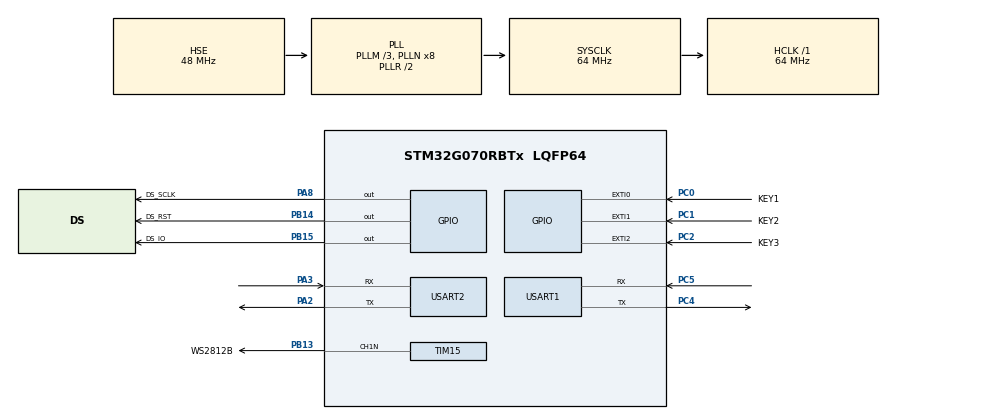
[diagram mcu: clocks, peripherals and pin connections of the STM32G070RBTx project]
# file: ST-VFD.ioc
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Dma.Request0=USART2_TX
Dma.Request1=USART2_RX
Dma.Request2=TIM15_CH1
Dma.TIM15_CH1.2.Direction=DMA_MEMORY_TO_PERIPH
Dma.TIM15_CH1.2.EventEnable=DISABLE
Dma.TIM15_CH1.2.Instance=DMA1_Channel3
Dma.TIM15_CH1.2.MemDataAlignment=DMA_MDATAALIGN_WORD
Dma.TIM15_CH1.2.MemInc=DMA_MINC_ENABLE
Dma.TIM15_CH1.2.Mode=DMA_NORMAL
Dma.TIM15_CH1.2.PeriphDataAlignment=DMA_PDATAALIGN_WORD
Dma.TIM15_CH1.2.PeriphInc=DMA_PINC_DISABLE
Dma.TIM15_CH1.2.Polarity=HAL_DMAMUX_REQ_GEN_RISING
Dma.TIM15_CH1.2.Priority=DMA_PRIORITY_LOW
Dma.TIM15_CH1.2.RequestNumber=1
Dma.TIM15_CH1.2.SignalID=NONE
Dma.TIM15_CH1.2.SyncEnable=DISABLE
Dma.TIM15_CH1.2.SyncPolarity=HAL_DMAMUX_SYNC_NO_EVENT
Dma.TIM15_CH1.2.SyncRequestNumber=1
Dma.TIM15_CH1.2.SyncSignalID=NONE
Dma.USART2_RX.1.Direction=DMA_PERIPH_TO_MEMORY
Dma.USART2_RX.1.EventEnable=DISABLE
Dma.USART2_RX.1.Instance=DMA1_Channel2
Dma.USART2_RX.1.MemDataAlignment=DMA_MDATAALIGN_BYTE
Dma.USART2_RX.1.MemInc=DMA_MINC_ENABLE
Dma.USART2_RX.1.Mode=DMA_NORMAL
Dma.USART2_RX.1.PeriphDataAlignment=DMA_PDATAALIGN_BYTE
Dma.USART2_RX.1.PeriphInc=DMA_PINC_DISABLE
Dma.USART2_RX.1.Polarity=HAL_DMAMUX_REQ_GEN_RISING
Dma.USART2_RX.1.Priority=DMA_PRIORITY_MEDIUM
Dma.USART2_RX.1.RequestNumber=1
Dma.USART2_RX.1.SignalID=NONE
Dma.USART2_RX.1.SyncEnable=DISABLE
Dma.USART2_RX.1.SyncPolarity=HAL_DMAMUX_SYNC_NO_EVENT
Dma.USART2_RX.1.SyncRequestNumber=1
Dma.USART2_RX.1.SyncSignalID=NONE
Dma.USART2_TX.0.Direction=DMA_MEMORY_TO_PERIPH
Dma.USART2_TX.0.EventEnable=DISABLE
Dma.USART2_TX.0.Instance=DMA1_Channel1
Dma.USART2_TX.0.MemDataAlignment=DMA_MDATAALIGN_BYTE
Dma.USART2_TX.0.MemInc=DMA_MINC_ENABLE
Dma.USART2_TX.0.Mode=DMA_NORMAL
Dma.USART2_TX.0.PeriphDataAlignment=DMA_PDATAALIGN_BYTE
Dma.USART2_TX.0.PeriphInc=DMA_PINC_DISABLE
Dma.USART2_TX.0.Polarity=HAL_DMAMUX_REQ_GEN_RISING
Dma.USART2_TX.0.Priority=DMA_PRIORITY_MEDIUM
Dma.USART2_TX.0.RequestNumber=1
Dma.USART2_TX.0.SignalID=NONE
Dma.USART2_TX.0.SyncEnable=DISABLE
Dma.USART2_TX.0.SyncPolarity=HAL_DMAMUX_SYNC_NO_EVENT
Dma.USART2_TX.0.SyncRequestNumber=1
Dma.USART2_TX.0.SyncSignalID=NONE
Mcu.Family=STM32G0
Mcu.Name=STM32G070RBTx
Mcu.Package=LQFP64
NVIC.DMA1_Channel1_IRQn=true\:0\:0\:false\:false\:true\:false\:true\:true
NVIC.DMA1_Channel2_3_IRQn=true\:0\:0\:false\:false\:true\:false\:true\:true
PA13.Mode=Serial_Wire
PA13.Signal=SYS_SWDIO
PA14-BOOT0.Mode=Serial_Wire
PA14-BOOT0.Signal=SYS_SWCLK
PA2.Mode=Asynchronous
PA2.Signal=USART2_TX
PA3.Mode=Asynchronous
PA3.Signal=USART2_RX
PA8.GPIO_Label=DS_SCLK
PA8.Signal=GPIO_Output
PB13.GPIO_Label=WS2812B
PB13.GPIO_Speed=GPIO_SPEED_FREQ_VERY_HIGH
PB13.Mode=PWM Generation1 CH1N
PB13.PinState=GPIO_PIN_RESET
PB13.Signal=TIM15_CH1N
PB14.GPIO_Label=DS_RST
PB14.Signal=GPIO_Output
PB15.GPIO_Label=DS_IO
PB15.Signal=GPIO_Output
PC0.GPIO_Label=KEY1
PC0.GPIO_ModeDefaultEXTI=GPIO_MODE_IT_FALLING
PC0.Signal=GPXTI0
PC1.GPIO_Label=KEY2
PC1.GPIO_ModeDefaultEXTI=GPIO_MODE_IT_FALLING
PC1.Signal=GPXTI1
PC2.GPIO_Label=KEY3
PC2.GPIO_ModeDefaultEXTI=GPIO_MODE_IT_FALLING
PC2.Signal=GPXTI2
PC4.Mode=Asynchronous
PC4.Signal=USART1_TX
PC5.Mode=Asynchronous
PC5.Signal=USART1_RX
PF0-OSC_IN\ (PF0).Mode=HSE-External-Oscillator
PF0-OSC_IN\ (PF0).Signal=RCC_OSC_IN
PF1-OSC_OUT\ (PF1).Mode=HSE-External-Oscillator
PF1-OSC_OUT\ (PF1).Signal=RCC_OSC_OUT
ProjectManager.HeapSize=0x200
ProjectManager.StackSize=0x400
ProjectManager.TargetToolchain=STM32CubeIDE
RCC.ADCFreq_Value=64000000
RCC.AHBFreq_Value=64000000
RCC.CortexFreq_Value=64000000
RCC.EXTERNAL_CLOCK_VALUE=48000
RCC.HCLKFreq_Value=64000000
RCC.HSE_VALUE=48000000
RCC.HSI_VALUE=16000000
RCC.LSE_VALUE=32768
RCC.PLLM=RCC_PLLM_DIV3
RCC.PLLSourceVirtual=RCC_PLLSOURCE_HSE
RCC.SYSCLKFreq_VALUE=64000000
RCC.SYSCLKSource=RCC_SYSCLKSOURCE_PLLCLK
RCC.VCOOutputFreq_Value=128000000
TIM15.Channel-PWM\ Generation1\ CH1N=TIM_CHANNEL_1
TIM15.Period=79
TIM6.Prescaler=63
USART1.VirtualMode-Asynchronous=VM_ASYNC
USART2.VirtualMode-Asynchronous=VM_ASYNC
VP_SYS_VS_DBSignals.Mode=DisableDeadBatterySignals
VP_TIM15_VS_ClockSourceINT.Mode=Internal
VP_TIM6_VS_ClockSourceINT.Mode=Enable_Timer
board=custom

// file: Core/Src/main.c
/* USER CODE BEGIN Header */
/**
  ******************************************************************************
  * @file           : main.c
  * @brief          : Main program body
  ******************************************************************************
  * @attention
  *
  * Copyright (c) 2023 STMicroelectronics.
  * All rights reserved.
  *
  * This software is licensed under terms that can be found in the LICENSE file
  * in the root directory of this software component.
  * If no LICENSE file comes with this software, it is provided AS-IS.
  *
  ******************************************************************************
  */
/* USER CODE END Header */
#include "main.h"
#include "dma.h"
#include "tim.h"
#include "usart.h"
#include "gpio.h"

/* USER CODE BEGIN Includes */
#include "index.h"
/* USER CODE END Includes */

void SystemClock_Config(void);

int main(void)
{

  /* MCU Configuration--------------------------------------------------------*/

  /* Reset of all peripherals, Initializes the Flash interface and the Systick. */
  HAL_Init();

  /* Configure the system clock */
  SystemClock_Config();

  /* Initialize all configured peripherals */
  MX_GPIO_Init();
  MX_DMA_Init();
  MX_USART1_UART_Init();
  MX_USART2_UART_Init();
  MX_TIM6_Init();
  MX_TIM15_Init();

  /* Infinite loop */
  /* USER CODE BEGIN WHILE */
  while (1)
  {
      Run_Service();
    /* USER CODE END WHILE */

  }
}

void SystemClock_Config(void)
{
  RCC_OscInitTypeDef RCC_OscInitStruct = {0};
  RCC_ClkInitTypeDef RCC_ClkInitStruct = {0};

  /** Configure the main internal regulator output voltage
  */
  HAL_PWREx_ControlVoltageScaling(PWR_REGULATOR_VOLTAGE_SCALE1);

  /** Initializes the RCC Oscillators according to the specified parameters
  * in the RCC_OscInitTypeDef structure.
  */
  RCC_OscInitStruct.OscillatorType = RCC_OSCILLATORTYPE_HSE;
  RCC_OscInitStruct.HSEState = RCC_HSE_ON;
  RCC_OscInitStruct.PLL.PLLState = RCC_PLL_ON;
  RCC_OscInitStruct.PLL.PLLSource = RCC_PLLSOURCE_HSE;
  RCC_OscInitStruct.PLL.PLLM = RCC_PLLM_DIV3;
  RCC_OscInitStruct.PLL.PLLN = 8;
  RCC_OscInitStruct.PLL.PLLP = RCC_PLLP_DIV2;
  RCC_OscInitStruct.PLL.PLLR = RCC_PLLR_DIV2;
  if (HAL_RCC_OscConfig(&RCC_OscInitStruct) != HAL_OK)
  {
    Error_Handler();
  }

  /** Initializes the CPU, AHB and APB buses clocks
  */
  RCC_ClkInitStruct.ClockType = RCC_CLOCKTYPE_HCLK|RCC_CLOCKTYPE_SYSCLK
                              |RCC_CLOCKTYPE_PCLK1;
  RCC_ClkInitStruct.SYSCLKSource = RCC_SYSCLKSOURCE_PLLCLK;
  RCC_ClkInitStruct.AHBCLKDivider = RCC_SYSCLK_DIV1;
  RCC_ClkInitStruct.APB1CLKDivider = RCC_HCLK_DIV1;

  if (HAL_RCC_ClockConfig(&RCC_ClkInitStruct, FLASH_LATENCY_2) != HAL_OK)
  {
    Error_Handler();
  }
}

/* USER CODE BEGIN 4 */
int __io_putchar(int ch) {
    HAL_UART_Transmit(&huart1, (uint8_t *) &ch, 1, 0xFFFF);
    return ch;
}
/* USER CODE END 4 */

void Error_Handler(void)
{
  /* USER CODE BEGIN Error_Handler_Debug */
  /* User can add his own implementation to report the HAL error return state */
  __disable_irq();
  while (1)
  {
      Error_Service_Handler();
  }
  /* USER CODE END Error_Handler_Debug */
}
